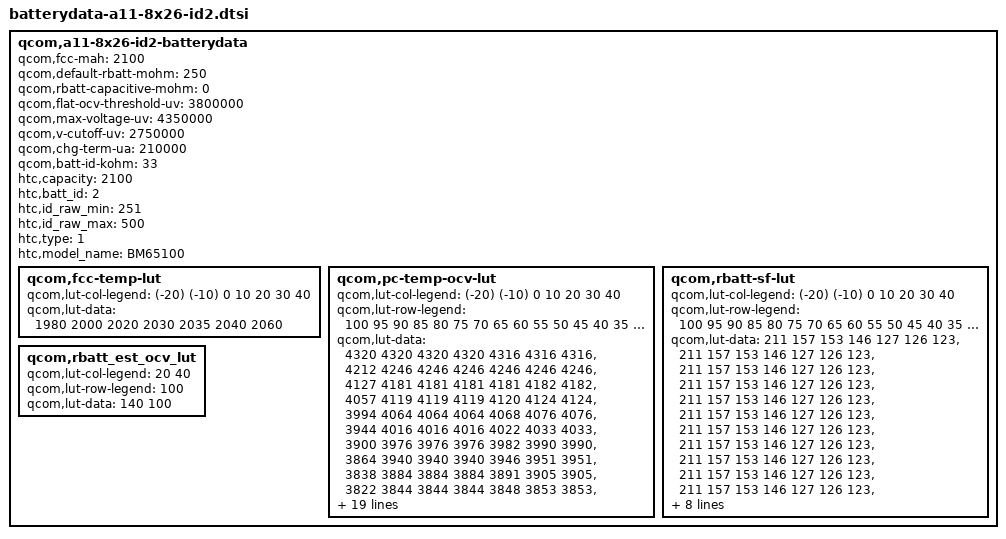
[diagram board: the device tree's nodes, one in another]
qcom,a11-8x26-id2-batterydata {
	qcom,fcc-mah = <2100>;
	qcom,default-rbatt-mohm = <250>;
	qcom,rbatt-capacitive-mohm = <0>;
	qcom,flat-ocv-threshold-uv = <3800000>;
	qcom,max-voltage-uv = <4350000>;
	qcom,v-cutoff-uv = <2750000>;
	qcom,chg-term-ua = <210000>;
	qcom,batt-id-kohm = <33>;
	htc,capacity = <2100>;
	htc,batt_id = <2>;
	htc,id_raw_min = <251>;
	htc,id_raw_max = <500>;
	htc,type = <1>;
	htc,model_name = "BM65100";


	qcom,fcc-temp-lut {
		qcom,lut-col-legend = <(-20) (-10) 0 10 20 30 40>;
		qcom,lut-data = <1980 2000 2020 2030 2035  2040 2060>;
	};

	qcom,pc-temp-ocv-lut {
		qcom,lut-col-legend = <(-20) (-10) 0 10 20 30 40>;
		qcom,lut-row-legend = <100 95 90 85 80 75 70 65 60 55 50 45 40 35 30 25 20 15 10 9 8 7 6 5 4 3 2 1 0>;
		qcom,lut-data =<4320 4320 4320 4320 4316 4316 4316>,
			<4212 4246 4246 4246 4246 4246 4246>,
			<4127 4181 4181 4181 4181 4182 4182>,
			<4057 4119 4119 4119 4120 4124 4124>,
			<3994 4064 4064 4064 4068 4076 4076>,
			<3944 4016 4016 4016 4022 4033 4033>,
			<3900 3976 3976 3976 3982 3990 3990>,
			<3864 3940 3940 3940 3946 3951 3951>,
			<3838 3884 3884 3884 3891 3905 3905>,
			<3822 3844 3844 3844 3848 3853 3853>,
			<3810 3820 3820 3820 3824 3827 3827>,
			<3799 3801 3801 3801 3804 3807 3807>,
			<3787 3787 3787 3787 3788 3790 3790>,
			<3778 3778 3778 3778 3778 3778 3778>,
			<3767 3767 3767 3767 3767 3767 3767>,
			<3751 3751 3751 3751 3751 3751 3751>,
			<3730 3732 3732 3732 3732 3732 3732>,
			<3702 3691 3691 3691 3691 3691 3691>,
			<3667 3629 3642 3661 3661 3661 3661>,
			<3661 3620 3632 3655 3655 3655 3655>,
			<3654 3610 3619 3648 3648 3648 3648>,
			<3645 3598 3604 3639 3639 3639 3639>,
			<3637 3585 3588 3631 3631 3631 3631>,
			<3624 3565 3565 3573 3586 3618 3618>,
			<3595 3528 3528 3523 3528 3556 3556>,
			<3567 3491 3491 3473 3469 3494 3494>,
			<3527 3440 3440 3404 3387 3408 3408>,
			<3465 3359 3359 3294 3258 3272 3272>,
			<3340 3198 3198 3075 3000 3000 3000>;

	};

	qcom,rbatt-sf-lut {
		qcom,lut-col-legend = <(-20) (-10) 0 10 20 30 40>;
		qcom,lut-row-legend = <100 95 90 85 80 75 70 65 60 55 50 45 40 35 30 25 20 15 10>;
		qcom,lut-data = <211 157 153 146 127 126 123>,
			<211 157 153 146 127 126 123>,
			<211 157 153 146 127 126 123>,
			<211 157 153 146 127 126 123>,
			<211 157 153 146 127 126 123>,
			<211 157 153 146 127 126 123>,
			<211 157 153 146 127 126 123>,
			<211 157 153 146 127 126 123>,
			<211 157 153 146 127 126 123>,
			<211 157 153 146 127 126 123>,
			<211 157 153 146 127 126 123>,
			<211 157 153 146 127 126 123>,
			<211 157 153 146 127 126 123>,
			<211 157 153 146 127 126 123>,
			<211 157 153 146 127 126 123>,
			<211 157 153 146 127 126 123>,
			<211 157 153 146 127 126 123>,
			<211 157 153 146 127 126 123>,
			<211 157 153 146 127 126 123>;
	};
	qcom,rbatt_est_ocv_lut {
		qcom,lut-col-legend = <20 40>;
		qcom,lut-row-legend = <100>;
		qcom,lut-data = <140 100>;
	};
};
